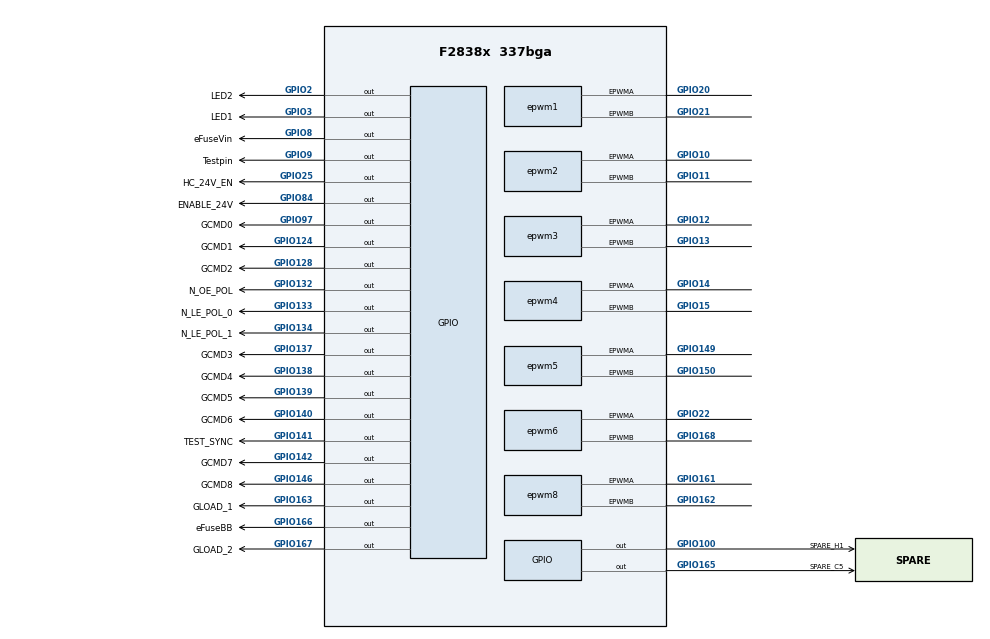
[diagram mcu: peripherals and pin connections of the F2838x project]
/**
 * @cliArgs --device "F2838x" --package "337bga" --part "F2838x_337bga" --context "CPU1" --product "C2000WARE@4.02.00.00"
 * @versions {"tool":"1.17.0+3128"}
 */

/**
 * Import the modules used in this configuration.
 */
const adc              = scripting.addModule("/driverlib/adc.js", {}, false);
const adc1             = adc.addInstance();
const adc2             = adc.addInstance();
const adc3             = adc.addInstance();
const adc4             = adc.addInstance();
const cputimer         = scripting.addModule("/driverlib/cputimer.js", {}, false);
const cputimer1        = cputimer.addInstance();
const epwm             = scripting.addModule("/driverlib/epwm.js", {}, false);
const epwm1            = epwm.addInstance();
const epwm2            = epwm.addInstance();
const epwm3            = epwm.addInstance();
const epwm4            = epwm.addInstance();
const epwm5            = epwm.addInstance();
const epwm6            = epwm.addInstance();
const epwm7            = epwm.addInstance();
const epwm8            = epwm.addInstance();
const gpio             = scripting.addModule("/driverlib/gpio.js", {}, false);
const gpio1            = gpio.addInstance();
const gpio2            = gpio.addInstance();
const gpio3            = gpio.addInstance();
const gpio4            = gpio.addInstance();
const gpio5            = gpio.addInstance();
const gpio6            = gpio.addInstance();
const gpio7            = gpio.addInstance();
const gpio8            = gpio.addInstance();
const gpio9            = gpio.addInstance();
const gpio10           = gpio.addInstance();
const gpio11           = gpio.addInstance();
const gpio12           = gpio.addInstance();
const gpio13           = gpio.addInstance();
const gpio14           = gpio.addInstance();
const gpio15           = gpio.addInstance();
const gpio16           = gpio.addInstance();
const gpio17           = gpio.addInstance();
const gpio18           = gpio.addInstance();
const gpio19           = gpio.addInstance();
const gpio20           = gpio.addInstance();
const gpio21           = gpio.addInstance();
const gpio22           = gpio.addInstance();
const gpio23           = gpio.addInstance();
const gpio24           = gpio.addInstance();
const inputxbar_input  = scripting.addModule("/driverlib/inputxbar_input.js", {}, false);
const inputxbar_input1 = inputxbar_input.addInstance();
const inputxbar_input2 = inputxbar_input.addInstance();
const inputxbar_input3 = inputxbar_input.addInstance();
const memcfg           = scripting.addModule("/driverlib/memcfg.js");

/**
 * Write custom configuration values to the imported modules.
 */
adc1.$name                          = "ADCINA";
adc1.interruptPulseMode             = "ADC_PULSE_END_OF_CONV";
adc1.adcResolutionMode              = "ADC_RESOLUTION_16BIT";
adc1.soc0UseCalculatedSampleTime    = true;
adc1.soc0InputCapacitance           = 1000;
adc1.soc0InputResistance            = 120;
adc1.adcClockPrescaler              = "ADC_CLK_DIV_2_0";
adc1.soc0SampleWindow               = 29;
adc1.adcSignalMode                  = "ADC_MODE_DIFFERENTIAL";
adc1.soc0Channel                    = "ADC_CH_ADCIN2_ADCIN3";
adc1.soc1Channel                    = "ADC_CH_ADCIN4_ADCIN5";
adc1.soc1SampleWindow               = 29;
adc1.registerInterrupts             = ["2"];
adc1.enabledInts                    = ["ADC_INT_NUMBER2"];
adc1.soc2Channel                    = "ADC_CH_ADCIN0_ADCIN1";
adc1.soc2SampleWindow               = 29;
adc1.enableInterrupt2               = true;
adc1.interrupt2SOCSource            = "ADC_SOC_NUMBER2";
adc1.soc0Trigger                    = "ADC_TRIGGER_EPWM12_SOCA";
adc1.soc2Trigger                    = "ADC_TRIGGER_EPWM12_SOCA";
adc1.enableInterrupt2ContinuousMode = true;
adc1.enabledSOCs                    = ["ADC_SOC_NUMBER0","ADC_SOC_NUMBER1"];
adc1.enableBurstMode                = true;
adc1.burstTrigger                   = "ADC_TRIGGER_EPWM12_SOCA";
adc1.burstSize                      = 1;
adc1.soc1Trigger                    = "ADC_TRIGGER_EPWM12_SOCA";
adc1.adcInt2.enableInterrupt        = true;

adc2.adcBase                 = "ADCB_BASE";
adc2.$name                   = "ADCINB";
adc2.soc0Channel             = "ADC_CH_ADCIN4";
adc2.soc0Trigger             = "ADC_TRIGGER_EPWM11_SOCA";
adc2.interruptCycleOffset    = 1;
adc2.enableInterrupt1        = true;
adc2.adcClockPrescaler       = "ADC_CLK_DIV_2_0";
adc2.soc2Trigger             = "ADC_TRIGGER_EPWM12_SOCA";
adc2.soc3Channel             = "ADC_CH_ADCIN5";
adc2.soc3Trigger             = "ADC_TRIGGER_EPWM12_SOCA";
adc2.soc4Channel             = "ADC_CH_ADCIN1";
adc2.interruptPulseMode      = "ADC_PULSE_END_OF_CONV";
adc2.soc2SampleWindow        = 15;
adc2.soc3SampleWindow        = 25;
adc2.enabledSOCs             = ["ADC_SOC_NUMBER0","ADC_SOC_NUMBER1"];
adc2.interrupt1SOCSource     = "ADC_SOC_NUMBER1";
adc2.soc1SampleWindow        = 15;
adc2.soc0SampleWindow        = 15;
adc2.enabledInts             = ["ADC_INT_NUMBER4"];
adc2.enableInterrupt4        = true;
adc2.adcResolutionMode       = "ADC_RESOLUTION_16BIT";
adc2.burstTrigger            = "ADC_TRIGGER_EPWM11_SOCA";
adc2.burstSize               = 1;
adc2.interrupt4SOCSource     = "ADC_SOC_NUMBER1";
adc2.soc1Trigger             = "ADC_TRIGGER_EPWM11_SOCA";
adc2.socHighPriorityMode     = "ADC_PRI_SOC0_HIPRI";
adc2.registerInterrupts      = ["4"];
adc2.adcInt4.enableInterrupt = true;

adc3.adcBase                 = "ADCD_BASE";
adc3.$name                   = "ADCIND";
adc3.adcClockPrescaler       = "ADC_CLK_DIV_2_0";
adc3.soc0SampleWindow        = 15;
adc3.soc1SampleWindow        = 15;
adc3.soc4Channel             = "ADC_CH_ADCIN3";
adc3.soc4Trigger             = "ADC_TRIGGER_EPWM12_SOCA";
adc3.soc4SampleWindow        = 20;
adc3.soc5Channel             = "ADC_CH_ADCIN5";
adc3.soc5Trigger             = "ADC_TRIGGER_EPWM12_SOCA";
adc3.soc5SampleWindow        = 20;
adc3.interrupt1SOCSource     = "ADC_SOC_NUMBER1";
adc3.enableInterrupt1        = true;
adc3.soc2SampleWindow        = 15;
adc3.soc3SampleWindow        = 15;
adc3.soc5Name                = "SOC5_I_DABZ3f";
adc3.soc4Name                = "SOC4_I_DABZ2f";
adc3.enabledSOCs             = ["ADC_SOC_NUMBER0","ADC_SOC_NUMBER1","ADC_SOC_NUMBER2","ADC_SOC_NUMBER3"];
adc3.enableInterrupt3        = true;
adc3.soc1Channel             = "ADC_CH_ADCIN1";
adc3.soc2Name                = "SOC2_IDAB2f";
adc3.soc2Channel             = "ADC_CH_ADCIN2";
adc3.soc3Channel             = "ADC_CH_ADCIN4";
adc3.adcResolutionMode       = "ADC_RESOLUTION_16BIT";
adc3.soc3Name                = "SOC3_IDAB3f";
adc3.interruptPulseMode      = "ADC_PULSE_END_OF_CONV";
adc3.enableInterrupt2        = true;
adc3.burstTrigger            = "ADC_TRIGGER_EPWM12_SOCA";
adc3.interrupt4SOCSource     = "ADC_SOC_NUMBER3";
adc3.registerInterrupts      = ["3"];
adc3.enabledInts             = ["ADC_INT_NUMBER3"];
adc3.interrupt3SOCSource     = "ADC_SOC_NUMBER3";
adc3.burstSize               = 3;
adc3.soc0Trigger             = "ADC_TRIGGER_EPWM12_SOCA";
adc3.enableBurstMode         = true;
adc3.soc1Trigger             = "ADC_TRIGGER_EPWM12_SOCA";
adc3.soc2Trigger             = "ADC_TRIGGER_EPWM12_SOCA";
adc3.soc3Trigger             = "ADC_TRIGGER_EPWM12_SOCA";
adc3.soc1Name                = "SOC1_V_Upf";
adc3.soc0Name                = "SOC0_V_DOWNf";
adc3.socHighPriorityMode     = "ADC_PRI_THRU_SOC1_HIPRI";
adc3.adcInt3.enableInterrupt = true;

adc4.$name                          = "ADCINC";
adc4.adcBase                        = "ADCC_BASE";
adc4.soc0Channel                    = "ADC_CH_ADCIN4";
adc4.soc1Channel                    = "ADC_CH_ADCIN5";
adc4.soc1Trigger                    = "ADC_TRIGGER_EPWM12_SOCA";
adc4.soc1SampleWindow               = 5;
adc4.interruptPulseMode             = "ADC_PULSE_END_OF_CONV";
adc4.enableInterrupt1               = true;
adc4.enabledInts                    = ["ADC_INT_NUMBER1"];
adc4.enabledSOCs                    = ["ADC_SOC_NUMBER0"];
adc4.soc0SampleWindow               = 15;
adc4.socHighPriorityMode            = "ADC_PRI_SOC0_HIPRI";
adc4.adcClockPrescaler              = "ADC_CLK_DIV_2_0";
adc4.adcResolutionMode              = "ADC_RESOLUTION_16BIT";
adc4.enableInterrupt1ContinuousMode = true;
adc4.soc0Trigger                    = "ADC_TRIGGER_EPWM12_SOCB";
adc4.registerInterrupts             = ["1"];
adc4.adcInt1.enableInterrupt        = true;

cputimer1.cputimerBase             = "CPUTIMER2_BASE";
cputimer1.timerPrescaler           = 1000;
cputimer1.timerPeriod              = 200;
cputimer1.registerInterrupts       = true;
cputimer1.startTimer               = true;
cputimer1.enableInterrupt          = true;
cputimer1.$name                    = "myCPUTIMER2";
cputimer1.timerInt.enableInterrupt = true;

epwm1.$name                                                               = "BEG_1_2";
epwm1.epwmTimebase_emulationMode                                          = "EPWM_EMULATION_FREE_RUN";
epwm1.epwmTimebase_period                                                 = 714;
epwm1.epwmActionQualifier_EPWM_AQ_OUTPUT_A_ON_TIMEBASE_ZERO               = "EPWM_AQ_OUTPUT_HIGH";
epwm1.epwmActionQualifier_EPWM_AQ_OUTPUT_A_ON_TIMEBASE_UP_CMPA            = "EPWM_AQ_OUTPUT_LOW";
epwm1.epwmDeadband_polarityFED                                            = "EPWM_DB_POLARITY_ACTIVE_LOW";
epwm1.epwmDeadband_delayRED                                               = 10;
epwm1.epwmDeadband_delayFED                                               = 10;
epwm1.epwmTimebase_hsClockDiv                                             = "EPWM_HSCLOCK_DIVIDER_1";
epwm1.epwmEventTrigger_EPWM_SOC_A_triggerEnable                           = true;
epwm1.epwmEventTrigger_EPWM_SOC_A_triggerSource                           = "EPWM_SOC_TBCTR_ZERO";
epwm1.epwmEventTrigger_EPWM_SOC_B_triggerEnable                           = true;
epwm1.epwmEventTrigger_EPWM_SOC_B_triggerSource                           = "EPWM_SOC_TBCTR_U_CMPA";
epwm1.epwmDeadband_enableRED                                              = true;
epwm1.epwmDeadband_enableFED                                              = true;
epwm1.epwmActionQualifier_EPWM_AQ_OUTPUT_A_shadowMode                     = true;
epwm1.epwmActionQualifier_EPWM_AQ_OUTPUT_A_shadowEvent                    = "EPWM_AQ_LOAD_ON_CNTR_PERIOD";
epwm1.epwmTimebase_syncInPulseSource                                      = "EPWM_SYNC_IN_PULSE_SRC_DISABLE";
epwm1.epwmTimebase_syncOutPulseMode                                       = ["EPWM_SYNC_OUT_PULSE_ON_CNTR_ZERO"];
epwm1.hrpwm_syncSource                                                    = "HRPWM_PWMSYNC_SOURCE_ZERO";
epwm1.epwmDigitalCompare_EPWM_TZ_DC_OUTPUT_A2                             = "EPWM_TZ_EVENT_DCXH_LOW";
epwm1.epwmDigitalCompare_EPWM_DC_MODULE_A_EPWM_DC_EVENT_1_latchMode       = "EPWM_DC_CBC_LATCH_ENABLED";
epwm1.epwmDigitalCompare_EPWM_DC_MODULE_A_EPWM_DC_EVENT_1_latchClearEvent = "EPWM_DC_CBC_LATCH_CLR_ON_CNTR_PERIOD";
epwm1.epwmDigitalCompare_EPWM_DC_MODULE_A_EPWM_DC_EVENT_2_latchMode       = "EPWM_DC_CBC_LATCH_ENABLED";
epwm1.epwmDigitalCompare_EPWM_DC_MODULE_A_EPWM_DC_EVENT_2_latchClearEvent = "EPWM_DC_CBC_LATCH_CLR_ON_CNTR_PERIOD";
epwm1.epwmDigitalCompare_EPWM_DC_MODULE_B_EPWM_DC_EVENT_1_latchMode       = "EPWM_DC_CBC_LATCH_ENABLED";
epwm1.epwmDigitalCompare_EPWM_DC_MODULE_B_EPWM_DC_EVENT_2_latchMode       = "EPWM_DC_CBC_LATCH_ENABLED";
epwm1.epwmEventTrigger_EPWM_SOC_A_triggerEventPrescalar                   = "2";
epwm1.epwmEventTrigger_EPWM_SOC_A_triggerEventCountInitEnable             = true;
epwm1.epwmEventTrigger_EPWM_SOC_B_triggerEventPrescalar                   = "2";
epwm1.epwmEventTrigger_EPWM_SOC_B_triggerEventCountInitEnable             = true;
epwm1.epwmCounterCompare_cmpB                                             = 2000;
epwm1.epwmTripZone_EPWM_TZ_ACTION_EVENT_TZA                               = "EPWM_TZ_ACTION_LOW";
epwm1.epwmTripZone_EPWM_TZ_ACTION_EVENT_TZB                               = "EPWM_TZ_ACTION_LOW";
epwm1.epwmTripZone_EPWM_TZ_ACTION_EVENT_DCAEVT1                           = "EPWM_TZ_ACTION_DISABLE";
epwm1.epwmTripZone_EPWM_TZ_ACTION_EVENT_DCAEVT2                           = "EPWM_TZ_ACTION_DISABLE";
epwm1.epwmTripZone_EPWM_TZ_ACTION_EVENT_DCBEVT1                           = "EPWM_TZ_ACTION_DISABLE";
epwm1.epwmTripZone_EPWM_TZ_ACTION_EVENT_DCBEVT2                           = "EPWM_TZ_ACTION_DISABLE";
epwm1.epwmActionQualifier_continousSwForceReloadMode                      = "EPWM_AQ_SW_IMMEDIATE_LOAD";
epwm1.epwmActionQualifier_EPWM_AQ_OUTPUT_B_ON_TIMEBASE_ZERO               = "EPWM_AQ_OUTPUT_LOW";
epwm1.epwmActionQualifier_EPWM_AQ_OUTPUT_B_shadowMode                     = true;
epwm1.epwmActionQualifier_EPWM_AQ_OUTPUT_B_shadowEvent                    = "EPWM_AQ_LOAD_ON_CNTR_PERIOD";
epwm1.epwmActionQualifier_EPWM_AQ_OUTPUT_B_ON_TIMEBASE_UP_CMPA            = "EPWM_AQ_OUTPUT_HIGH";
epwm1.epwmCounterCompare_cmpA                                             = 1;
epwm1.epwm.$assign                                                        = "EPWM11";
epwm1.epwm.epwmaPin.$assign                                               = "GPIO20";
epwm1.epwm.epwmbPin.$assign                                               = "GPIO21";

epwm2.$name                                                    = "QABPWM_12_13";
epwm2.epwmTimebase_emulationMode                               = "EPWM_EMULATION_FREE_RUN";
epwm2.epwmTimebase_hsClockDiv                                  = "EPWM_HSCLOCK_DIVIDER_1";
epwm2.epwmTimebase_period                                      = 386;
epwm2.epwmTimebase_phaseEnable                                 = true;
epwm2.epwmTimebase_forceSyncPulse                              = true;
epwm2.epwmTimebase_syncInPulseSource                           = "EPWM_SYNC_IN_PULSE_SRC_DISABLE";
epwm2.epwmCounterCompare_cmpA                                  = 193;
epwm2.epwmActionQualifier_EPWM_AQ_OUTPUT_A_ON_TIMEBASE_ZERO    = "EPWM_AQ_OUTPUT_HIGH";
epwm2.epwmActionQualifier_EPWM_AQ_OUTPUT_A_ON_TIMEBASE_UP_CMPA = "EPWM_AQ_OUTPUT_LOW";
epwm2.epwmTripZone_EPWM_TZ_ACTION_EVENT_TZA                    = "EPWM_TZ_ACTION_LOW";
epwm2.epwmTripZone_EPWM_TZ_ACTION_EVENT_TZB                    = "EPWM_TZ_ACTION_LOW";
epwm2.epwmDeadband_polarityFED                                 = "EPWM_DB_POLARITY_ACTIVE_LOW";
epwm2.epwmDeadband_enableRED                                   = true;
epwm2.epwmDeadband_delayRED                                    = 4;
epwm2.epwmDeadband_enableFED                                   = true;
epwm2.epwmDeadband_delayFED                                    = 4;
epwm2.epwmTimebase_counterMode                                 = "EPWM_COUNTER_MODE_UP";
epwm2.epwmTimebase_syncOutPulseMode                            = ["EPWM_SYNC_OUT_PULSE_ON_CNTR_ZERO"];
epwm2.hrpwm_syncSource                                         = "HRPWM_PWMSYNC_SOURCE_ZERO";
epwm2.epwmActionQualifier_EPWM_AQ_OUTPUT_B_ON_TIMEBASE_ZERO    = "EPWM_AQ_OUTPUT_LOW";
epwm2.epwmActionQualifier_EPWM_AQ_OUTPUT_B_ON_TIMEBASE_UP_CMPA = "EPWM_AQ_OUTPUT_HIGH";
epwm2.epwmTripZone_EPWM_TZ_ACTION_EVENT_DCAEVT1                = "EPWM_TZ_ACTION_DISABLE";
epwm2.epwmTripZone_EPWM_TZ_ACTION_EVENT_DCAEVT2                = "EPWM_TZ_ACTION_DISABLE";
epwm2.epwmTripZone_EPWM_TZ_ACTION_EVENT_DCBEVT1                = "EPWM_TZ_ACTION_DISABLE";
epwm2.epwmTripZone_EPWM_TZ_ACTION_EVENT_DCBEVT2                = "EPWM_TZ_ACTION_DISABLE";
epwm2.epwm.$assign                                             = "EPWM6";
epwm2.epwm.epwmaPin.$assign                                    = "GPIO10";
epwm2.epwm.epwmbPin.$assign                                    = "GPIO11";

epwm3.$name                                                    = "QABPWM_14_15";
epwm3.epwmTimebase_emulationMode                               = "EPWM_EMULATION_FREE_RUN";
epwm3.epwmTimebase_hsClockDiv                                  = "EPWM_HSCLOCK_DIVIDER_1";
epwm3.epwmTimebase_period                                      = 386;
epwm3.epwmTimebase_phaseEnable                                 = true;
epwm3.epwmTimebase_periodLink                                  = "EPWM_LINK_WITH_EPWM_6";
epwm3.epwmTimebase_syncInPulseSource                           = "EPWM_SYNC_IN_PULSE_SRC_SYNCOUT_EPWM6";
epwm3.epwmCounterCompare_cmpA                                  = 193;
epwm3.epwmCounterCompare_cmpALink                              = "EPWM_LINK_WITH_EPWM_6";
epwm3.epwmDeadband_polarityFED                                 = "EPWM_DB_POLARITY_ACTIVE_LOW";
epwm3.epwmDeadband_enableRED                                   = true;
epwm3.epwmDeadband_delayRED                                    = 4;
epwm3.epwmDeadband_enableFED                                   = true;
epwm3.epwmDeadband_delayFED                                    = 4;
epwm3.epwmTimebase_counterMode                                 = "EPWM_COUNTER_MODE_UP";
epwm3.hrpwm_syncSource                                         = "HRPWM_PWMSYNC_SOURCE_ZERO";
epwm3.epwmActionQualifier_EPWM_AQ_OUTPUT_A_ON_TIMEBASE_ZERO    = "EPWM_AQ_OUTPUT_LOW";
epwm3.epwmActionQualifier_EPWM_AQ_OUTPUT_A_ON_TIMEBASE_UP_CMPA = "EPWM_AQ_OUTPUT_HIGH";
epwm3.epwmActionQualifier_EPWM_AQ_OUTPUT_B_ON_TIMEBASE_ZERO    = "EPWM_AQ_OUTPUT_HIGH";
epwm3.epwmActionQualifier_EPWM_AQ_OUTPUT_B_ON_TIMEBASE_UP_CMPA = "EPWM_AQ_OUTPUT_LOW";
epwm3.epwmTripZone_EPWM_TZ_ACTION_EVENT_TZA                    = "EPWM_TZ_ACTION_LOW";
epwm3.epwmTripZone_EPWM_TZ_ACTION_EVENT_TZB                    = "EPWM_TZ_ACTION_LOW";
epwm3.epwmTripZone_EPWM_TZ_ACTION_EVENT_DCAEVT1                = "EPWM_TZ_ACTION_DISABLE";
epwm3.epwmTripZone_EPWM_TZ_ACTION_EVENT_DCAEVT2                = "EPWM_TZ_ACTION_DISABLE";
epwm3.epwmTripZone_EPWM_TZ_ACTION_EVENT_DCBEVT1                = "EPWM_TZ_ACTION_DISABLE";
epwm3.epwmTripZone_EPWM_TZ_ACTION_EVENT_DCBEVT2                = "EPWM_TZ_ACTION_DISABLE";
epwm3.epwm.$assign                                             = "EPWM7";
epwm3.epwm.epwmaPin.$assign                                    = "GPIO12";
epwm3.epwm.epwmbPin.$assign                                    = "GPIO13";

epwm4.$name                                                    = "QABPWM_4_5";
epwm4.epwmTimebase_emulationMode                               = "EPWM_EMULATION_FREE_RUN";
epwm4.epwmTimebase_hsClockDiv                                  = "EPWM_HSCLOCK_DIVIDER_1";
epwm4.epwmTimebase_period                                      = 386;
epwm4.epwmTimebase_phaseEnable                                 = true;
epwm4.epwmTimebase_forceSyncPulse                              = true;
epwm4.epwmTimebase_syncInPulseSource                           = "EPWM_SYNC_IN_PULSE_SRC_DISABLE";
epwm4.epwmCounterCompare_cmpA                                  = 193;
epwm4.epwmActionQualifier_EPWM_AQ_OUTPUT_A_ON_TIMEBASE_ZERO    = "EPWM_AQ_OUTPUT_HIGH";
epwm4.epwmActionQualifier_EPWM_AQ_OUTPUT_A_ON_TIMEBASE_UP_CMPA = "EPWM_AQ_OUTPUT_LOW";
epwm4.epwmTripZone_EPWM_TZ_ACTION_EVENT_TZA                    = "EPWM_TZ_ACTION_LOW";
epwm4.epwmTripZone_EPWM_TZ_ACTION_EVENT_TZB                    = "EPWM_TZ_ACTION_LOW";
epwm4.epwmDeadband_polarityFED                                 = "EPWM_DB_POLARITY_ACTIVE_LOW";
epwm4.epwmDeadband_delayRED                                    = 4;
epwm4.epwmDeadband_enableFED                                   = true;
epwm4.epwmDeadband_delayFED                                    = 4;
epwm4.epwmTimebase_syncOutPulseMode                            = ["EPWM_SYNC_OUT_PULSE_ON_CNTR_ZERO"];
epwm4.hrpwm_syncSource                                         = "HRPWM_PWMSYNC_SOURCE_ZERO";
epwm4.epwmActionQualifier_EPWM_AQ_OUTPUT_B_ON_TIMEBASE_ZERO    = "EPWM_AQ_OUTPUT_LOW";
epwm4.epwmActionQualifier_EPWM_AQ_OUTPUT_B_ON_TIMEBASE_UP_CMPA = "EPWM_AQ_OUTPUT_HIGH";
epwm4.epwmDeadband_enableRED                                   = true;
epwm4.epwmTimebase_counterMode                                 = "EPWM_COUNTER_MODE_UP";
epwm4.epwmTripZone_EPWM_TZ_ACTION_EVENT_DCAEVT1                = "EPWM_TZ_ACTION_DISABLE";
epwm4.epwmTripZone_EPWM_TZ_ACTION_EVENT_DCAEVT2                = "EPWM_TZ_ACTION_DISABLE";
epwm4.epwmTripZone_EPWM_TZ_ACTION_EVENT_DCBEVT1                = "EPWM_TZ_ACTION_DISABLE";
epwm4.epwmTripZone_EPWM_TZ_ACTION_EVENT_DCBEVT2                = "EPWM_TZ_ACTION_DISABLE";
epwm4.epwm.$assign                                             = "EPWM8";
epwm4.epwm.epwmaPin.$assign                                    = "GPIO14";
epwm4.epwm.epwmbPin.$assign                                    = "GPIO15";

epwm5.$name                                                    = "QABPWM_6_7";
epwm5.epwmTimebase_emulationMode                               = "EPWM_EMULATION_FREE_RUN";
epwm5.epwmTimebase_hsClockDiv                                  = "EPWM_HSCLOCK_DIVIDER_1";
epwm5.epwmTimebase_period                                      = 386;
epwm5.epwmTimebase_phaseEnable                                 = true;
epwm5.epwmTimebase_periodLink                                  = "EPWM_LINK_WITH_EPWM_8";
epwm5.epwmTimebase_syncInPulseSource                           = "EPWM_SYNC_IN_PULSE_SRC_SYNCOUT_EPWM8";
epwm5.epwmCounterCompare_cmpA                                  = 193;
epwm5.epwmCounterCompare_cmpALink                              = "EPWM_LINK_WITH_EPWM_8";
epwm5.epwmDeadband_polarityFED                                 = "EPWM_DB_POLARITY_ACTIVE_LOW";
epwm5.epwmDeadband_enableRED                                   = true;
epwm5.epwmDeadband_delayRED                                    = 4;
epwm5.epwmDeadband_enableFED                                   = true;
epwm5.epwmDeadband_delayFED                                    = 4;
epwm5.hrpwm_syncSource                                         = "HRPWM_PWMSYNC_SOURCE_ZERO";
epwm5.epwmActionQualifier_EPWM_AQ_OUTPUT_A_ON_TIMEBASE_ZERO    = "EPWM_AQ_OUTPUT_LOW";
epwm5.epwmActionQualifier_EPWM_AQ_OUTPUT_A_ON_TIMEBASE_UP_CMPA = "EPWM_AQ_OUTPUT_HIGH";
epwm5.epwmActionQualifier_EPWM_AQ_OUTPUT_B_ON_TIMEBASE_ZERO    = "EPWM_AQ_OUTPUT_HIGH";
epwm5.epwmActionQualifier_EPWM_AQ_OUTPUT_B_ON_TIMEBASE_UP_CMPA = "EPWM_AQ_OUTPUT_LOW";
epwm5.epwmTripZone_EPWM_TZ_ACTION_EVENT_TZA                    = "EPWM_TZ_ACTION_LOW";
epwm5.epwmTripZone_EPWM_TZ_ACTION_EVENT_TZB                    = "EPWM_TZ_ACTION_LOW";
epwm5.epwmGlobalLoad_gld                                       = true;
epwm5.epwmTimebase_counterMode                                 = "EPWM_COUNTER_MODE_UP";
epwm5.epwmTripZone_EPWM_TZ_ACTION_EVENT_DCAEVT1                = "EPWM_TZ_ACTION_DISABLE";
epwm5.epwmTripZone_EPWM_TZ_ACTION_EVENT_DCAEVT2                = "EPWM_TZ_ACTION_DISABLE";
epwm5.epwmTripZone_EPWM_TZ_ACTION_EVENT_DCBEVT1                = "EPWM_TZ_ACTION_DISABLE";
epwm5.epwmTripZone_EPWM_TZ_ACTION_EVENT_DCBEVT2                = "EPWM_TZ_ACTION_DISABLE";
epwm5.epwm.$assign                                             = "EPWM3";
epwm5.epwm.epwmaPin.$assign                                    = "GPIO149";
epwm5.epwm.epwmbPin.$assign                                    = "GPIO150";

epwm6.$name                                                    = "InrushCurrentLimit";
epwm6.copyFrom                                                 = "BEG_1_2";
epwm6.epwmTimebase_hsClockDiv                                  = "EPWM_HSCLOCK_DIVIDER_1";
epwm6.epwmActionQualifier_EPWM_AQ_OUTPUT_B_ON_TIMEBASE_ZERO    = "EPWM_AQ_OUTPUT_HIGH";
epwm6.epwmEventTrigger_EPWM_SOC_A_triggerEnable                = true;
epwm6.epwmEventTrigger_EPWM_SOC_A_triggerSource                = "EPWM_SOC_TBCTR_ZERO";
epwm6.epwmTimebase_period                                      = 10000;
epwm6.epwmCounterCompare_cmpC                                  = 8500;
epwm6.epwmActionQualifier_EPWM_AQ_OUTPUT_B_ON_TIMEBASE_UP_CMPA = "EPWM_AQ_OUTPUT_LOW";
epwm6.epwmDeadband_inputRED                                    = "EPWM_DB_INPUT_EPWMB";
epwm6.epwmDeadband_inputFED                                    = "EPWM_DB_INPUT_EPWMB";
epwm6.epwmEventTrigger_EPWM_SOC_A_triggerEventPrescalar        = "1";
epwm6.epwmEventTrigger_EPWM_SOC_B_triggerEnable                = true;
epwm6.epwmEventTrigger_EPWM_SOC_B_triggerSource                = "EPWM_SOC_TBCTR_U_CMPC";
epwm6.epwmEventTrigger_EPWM_SOC_B_triggerEventPrescalar        = "1";
epwm6.epwmTimebase_counterValue                                = 1;
epwm6.epwmTripZone_EPWM_TZ_ACTION_EVENT_DCAEVT1                = "EPWM_TZ_ACTION_DISABLE";
epwm6.epwmTripZone_EPWM_TZ_ACTION_EVENT_DCAEVT2                = "EPWM_TZ_ACTION_DISABLE";
epwm6.epwmTripZone_EPWM_TZ_ACTION_EVENT_DCBEVT1                = "EPWM_TZ_ACTION_DISABLE";
epwm6.epwmTripZone_EPWM_TZ_ACTION_EVENT_DCBEVT2                = "EPWM_TZ_ACTION_DISABLE";
epwm6.epwmTripZone_EPWM_TZ_ACTION_EVENT_TZA                    = "EPWM_TZ_ACTION_LOW";
epwm6.epwmTripZone_EPWM_TZ_ACTION_EVENT_TZB                    = "EPWM_TZ_ACTION_LOW";
epwm6.epwm.$assign                                             = "EPWM12";
epwm6.epwm.epwmaPin.$assign                                    = "GPIO22";
epwm6.epwm.epwmbPin.$assign                                    = "GPIO168";

epwm7.$name                                             = "EPWMTimer";
epwm7.epwmTimebase_hsClockDiv                           = "EPWM_HSCLOCK_DIVIDER_1";
epwm7.epwmTimebase_period                               = 1000;
epwm7.epwmTimebase_periodLink                           = "EPWM_LINK_WITH_EPWM_11";
epwm7.epwmTimebase_forceSyncPulse                       = true;
epwm7.epwmTimebase_syncInPulseSource                    = "EPWM_SYNC_IN_PULSE_SRC_SYNCOUT_EPWM11";
epwm7.epwmCounterCompare_cmpA                           = 800;
epwm7.epwmCounterCompare_cmpBLink                       = "EPWM_LINK_WITH_EPWM_11";
epwm7.epwmCounterCompare_cmpCLink                       = "EPWM_LINK_WITH_EPWM_11";
epwm7.epwmCounterCompare_cmpDLink                       = "EPWM_LINK_WITH_EPWM_11";
epwm7.epwmEventTrigger_enableInterrupt                  = true;
epwm7.epwmEventTrigger_EPWM_SOC_A_triggerEnable         = true;
epwm7.epwmEventTrigger_EPWM_SOC_A_triggerSource         = "EPWM_SOC_TBCTR_U_CMPA";
epwm7.epwmEventTrigger_EPWM_SOC_B_triggerEnable         = true;
epwm7.epwmEventTrigger_EPWM_SOC_B_triggerSource         = "EPWM_SOC_TBCTR_ZERO";
epwm7.epwmEventTrigger_EPWM_SOC_A_triggerEventPrescalar = "15";
epwm7.epwmEventTrigger_EPWM_SOC_B_triggerEventPrescalar = "15";
epwm7.epwm.$assign                                      = "EPWM16";

epwm8.$name                                                    = "GLOAD_4_3";
epwm8.epwmDeadband_inputRED                                    = "EPWM_DB_INPUT_EPWMB";
epwm8.epwmDeadband_inputFED                                    = "EPWM_DB_INPUT_DB_RED";
epwm8.epwmTimebase_emulationMode                               = "EPWM_EMULATION_FREE_RUN";
epwm8.epwmTimebase_hsClockDiv                                  = "EPWM_HSCLOCK_DIVIDER_1";
epwm8.epwmTimebase_counterValue                                = 1;
epwm8.epwmTimebase_syncInPulseSource                           = "EPWM_SYNC_IN_PULSE_SRC_DISABLE";
epwm8.epwmTimebase_syncOutPulseMode                            = ["EPWM_SYNC_OUT_PULSE_ON_CNTR_ZERO"];
epwm8.hrpwm_syncSource                                         = "HRPWM_PWMSYNC_SOURCE_ZERO";
epwm8.epwmActionQualifier_EPWM_AQ_OUTPUT_A_shadowMode          = true;
epwm8.epwmActionQualifier_EPWM_AQ_OUTPUT_A_shadowEvent         = "EPWM_AQ_LOAD_ON_CNTR_PERIOD";
epwm8.epwmActionQualifier_EPWM_AQ_OUTPUT_A_ON_TIMEBASE_ZERO    = "EPWM_AQ_OUTPUT_HIGH";
epwm8.epwmActionQualifier_EPWM_AQ_OUTPUT_A_ON_TIMEBASE_UP_CMPA = "EPWM_AQ_OUTPUT_LOW";
epwm8.epwmActionQualifier_EPWM_AQ_OUTPUT_B_shadowMode          = true;
epwm8.epwmActionQualifier_EPWM_AQ_OUTPUT_B_shadowEvent         = "EPWM_AQ_LOAD_ON_CNTR_PERIOD";
epwm8.epwmActionQualifier_EPWM_AQ_OUTPUT_B_ON_TIMEBASE_ZERO    = "EPWM_AQ_OUTPUT_HIGH";
epwm8.epwmActionQualifier_EPWM_AQ_OUTPUT_B_ON_TIMEBASE_UP_CMPB = "EPWM_AQ_OUTPUT_LOW";
epwm8.epwmCounterCompare_cmpA                                  = 10001;
epwm8.epwmCounterCompare_cmpB                                  = 10001;
epwm8.epwmTripZone_registerInterrupts                          = true;
epwm8.epwmActionQualifier_continousSwForceReloadMode           = "EPWM_AQ_SW_IMMEDIATE_LOAD";
epwm8.epwmTripZone_EPWM_TZ_ACTION_EVENT_TZA                    = "EPWM_TZ_ACTION_DISABLE";
epwm8.epwmTripZone_EPWM_TZ_ACTION_EVENT_TZB                    = "EPWM_TZ_ACTION_DISABLE";
epwm8.epwmTripZone_oneShotSource                               = ["EPWM_TZ_SIGNAL_OSHT1"];
epwm8.epwmTripZone_tzInterruptSource                           = ["EPWM_TZ_INTERRUPT_OST"];
epwm8.epwmTimebase_period                                      = 10;
epwm8.epwm.$assign                                             = "EPWM9";
epwm8.epwm.epwmaPin.$assign                                    = "GPIO161";
epwm8.epwm.epwmbPin.$assign                                    = "GPIO162";
epwm8.epwmTZInt.enableInterrupt                                = true;

gpio1.masterCore      = "GPIO_CORE_CPU2";
gpio1.$name           = "eFuseVin";
gpio1.gpioPin.$assign = "GPIO8";

gpio2.$name           = "HC_24V_EN";
gpio2.gpioPin.$assign = "GPIO25";

gpio3.$name           = "ENABLE_24V";
gpio3.gpioPin.$assign = "GPIO84";

gpio4.$name           = "GCMD0";
gpio4.direction       = "GPIO_DIR_MODE_OUT";
gpio4.masterCore      = "GPIO_CORE_CPU2";
gpio4.gpioPin.$assign = "GPIO97";

gpio5.$name           = "GCMD1";
gpio5.direction       = "GPIO_DIR_MODE_OUT";
gpio5.masterCore      = "GPIO_CORE_CPU2";
gpio5.gpioPin.$assign = "GPIO124";

gpio6.$name           = "GCMD2";
gpio6.direction       = "GPIO_DIR_MODE_OUT";
gpio6.masterCore      = "GPIO_CORE_CPU2";
gpio6.gpioPin.$assign = "GPIO128";

gpio7.$name           = "GCMD3";
gpio7.direction       = "GPIO_DIR_MODE_OUT";
gpio7.masterCore      = "GPIO_CORE_CPU2";
gpio7.gpioPin.$assign = "GPIO137";

gpio8.$name           = "GCMD4";
gpio8.direction       = "GPIO_DIR_MODE_OUT";
gpio8.masterCore      = "GPIO_CORE_CPU2";
gpio8.gpioPin.$assign = "GPIO138";

gpio9.$name           = "GCMD5";
gpio9.direction       = "GPIO_DIR_MODE_OUT";
gpio9.masterCore      = "GPIO_CORE_CPU2";
gpio9.gpioPin.$assign = "GPIO139";

gpio10.$name           = "GCMD6";
gpio10.direction       = "GPIO_DIR_MODE_OUT";
gpio10.masterCore      = "GPIO_CORE_CPU2";
gpio10.gpioPin.$assign = "GPIO140";

gpio11.$name             = "GCMD7";
gpio11.direction         = "GPIO_DIR_MODE_OUT";
gpio11.writeInitialValue = true;
gpio11.initialValue      = 1;
gpio11.masterCore        = "GPIO_CORE_CPU2";
gpio11.gpioPin.$assign   = "GPIO142";

gpio12.$name           = "SPARE_H1";
gpio12.masterCore      = "GPIO_CORE_CPU2";
gpio12.gpioPin.$assign = "GPIO100";

gpio13.$name           = "SPARE_C5";
gpio13.gpioPin.$assign = "GPIO165";

gpio14.$name                     = "eFuseBB";
gpio14.useInterrupt              = true;
gpio14.masterCore                = "GPIO_CORE_CPU2";
gpio14.gpioPin.$assign           = "GPIO166";
gpio14.xint.enableInt            = true;
gpio14.xint.registerInterrupts   = true;
gpio14.xint.xintNum              = "GPIO_INT_XINT5";
gpio14.xint.xInt.enableInterrupt = true;

gpio15.$name           = "GLOAD_2";
gpio15.direction       = "GPIO_DIR_MODE_OUT";
gpio15.masterCore      = "GPIO_CORE_CPU2";
gpio15.gpioPin.$assign = "GPIO167";

gpio16.$name             = "N_OE_POL";
gpio16.direction         = "GPIO_DIR_MODE_OUT";
gpio16.writeInitialValue = true;
gpio16.initialValue      = 1;
gpio16.masterCore        = "GPIO_CORE_CPU2";
gpio16.gpioPin.$assign   = "GPIO132";

gpio17.$name           = "N_LE_POL_0";
gpio17.direction       = "GPIO_DIR_MODE_OUT";
gpio17.masterCore      = "GPIO_CORE_CPU2";
gpio17.gpioPin.$assign = "GPIO133";

gpio18.$name           = "N_LE_POL_1";
gpio18.direction       = "GPIO_DIR_MODE_OUT";
gpio18.masterCore      = "GPIO_CORE_CPU2";
gpio18.gpioPin.$assign = "GPIO134";

gpio19.$name           = "Testpin";
gpio19.direction       = "GPIO_DIR_MODE_OUT";
gpio19.masterCore      = "GPIO_CORE_CPU2";
gpio19.gpioPin.$assign = "GPIO9";

gpio20.$name           = "GLOAD_1";
gpio20.direction       = "GPIO_DIR_MODE_OUT";
gpio20.masterCore      = "GPIO_CORE_CPU2";
gpio20.gpioPin.$assign = "GPIO163";

gpio21.$name           = "GCMD8";
gpio21.masterCore      = "GPIO_CORE_CPU2";
gpio21.direction       = "GPIO_DIR_MODE_OUT";
gpio21.gpioPin.$assign = "GPIO146";

gpio22.$name           = "TEST_SYNC";
gpio22.gpioPin.$assign = "GPIO141";

gpio23.$name           = "LED2";
gpio23.masterCore      = "GPIO_CORE_CPU2";
gpio23.gpioPin.$assign = "GPIO2";

gpio24.$name           = "LED1";
gpio24.gpioPin.$assign = "GPIO3";

inputxbar_input1.inputxbarGpio = "GPIO8";
inputxbar_input1.inputxbarLock = true;
inputxbar_input1.$name         = "EFUSE_VIN_TRIP1";

inputxbar_input2.$name          = "Trip2";
inputxbar_input2.inputxbarInput = "XBAR_INPUT2";
inputxbar_input2.inputxbarGpio  = "GPIO2";

inputxbar_input3.inputxbarGpio = "GPIO166";
inputxbar_input3.$name         = "EFUSE_BB_TRIP3";
inputxbar_input3.inputxbarLock = true;
gpio14.xint.inputxbar          = inputxbar_input3;

memcfg.config_MEMCFG_SECT_GS1 = "MEMCFG_GSRAMMASTER_CPU2";
memcfg.config_MEMCFG_SECT_GS3 = "MEMCFG_GSRAMMASTER_CPU2";

/**
 * Pinmux solution for unlocked pins/peripherals. This ensures that minor changes to the automatic solver in a future
 * version of the tool will not impact the pinmux you originally saw.  These lines can be completely deleted in order to
 * re-solve from scratch.
 */
epwm7.epwm.epwmaPin.$suggestSolution = "GPIO143";
epwm7.epwm.epwmbPin.$suggestSolution = "GPIO144";
